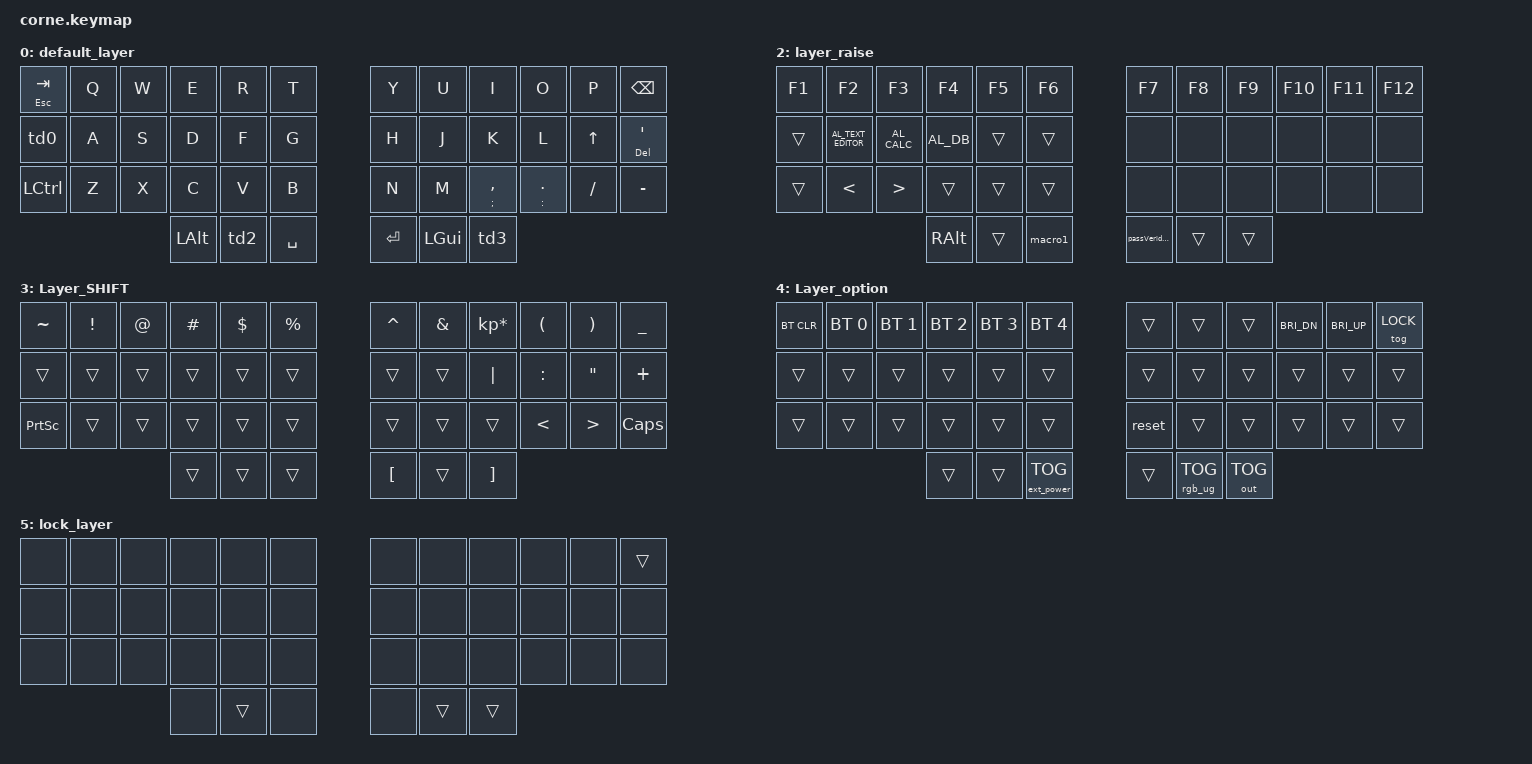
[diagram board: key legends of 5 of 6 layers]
//https://zmk.dev/docs/codes
//https://zmk.dev/docs/development/new-shield

#include <behaviors.dtsi>
#include <dt-bindings/zmk/keys.h>
#include <dt-bindings/zmk/bt.h>
#include <dt-bindings/zmk/rgb.h>
#include <dt-bindings/zmk/backlight.h>
#include <dt-bindings/zmk/ext_power.h>
#include <dt-bindings/zmk/outputs.h>
#include <dt-bindings/zmk/mouse.h>

#define LOWER 1
#define RAISE 2
#define SHIFT 3
#define OPTION 4
#define LOCK 5

/*
&mt es una abreviatura de "mod-tap". Este comportamiento permite que una tecla funcione como un modificador 
(como Shift, Ctrl, Alt, etc.) cuando se mantiene presionada, y como una tecla normal cuando se pulsa y se suelta 
rápidamente. Por ejemplo, &mt LSFT A hará que una tecla funcione como "A" cuando se pulsa y se suelta rápidamente, 
y como Shift izquierdo cuando se mantiene presionada.

&kt es una abreviatura de "key tap". Este comportamiento permite que una tecla funcione como una tecla normal cuando 
se pulsa y se suelta rápidamente, pero también puede tener un comportamiento diferente si se mantiene presionada. Sin 
embargo, a diferencia de &mt, &kt no está limitado a los modificadores y puede asignar cualquier comportamiento a la 
acción de mantener presionada.

Por lo tanto, la principal diferencia entre &mt y &kt es que &mt está limitado a los modificadores para la acción de 
mantener presionada, mientras que &kt puede asignar cualquier comportamiento a la acción de mantener presionada.
*/

&mmv {    
        time-to-max-speed-ms = <1000>;
        acceleration-exponent=<1>;
};
&mwh {    
        time-to-max-speed-ms = <2000>;
        acceleration-exponent=<0>;
}; 
/ {
    behaviors {
        ht: hold-tap {
            compatible = "zmk,behavior-hold-tap";
            label = "hold-tap";
            #binding-cells = <2>;
            tapping_term_ms = <200>;
            //flavor = "tap-preferred"; por defecto en situaciones ambiguas que haga el hold
            bindings =
                <&kp>,
                <&kp>;
        };
        td0: tap_dance_CAPSLOCK {
            compatible = "zmk,behavior-tap-dance";
            #binding-cells = <0>;
            tapping-term-ms = <200>;
            bindings = <&kp LSHFT>, <&kp CAPSLOCK>;
        };

        td1: tap_dance { //generico
            compatible = "zmk,behavior-tap-dance";
            #binding-cells = <2>;
            tapping-term-ms = <200>;
            bindings = <&kp >, <&kp >;
        };

        td2:tap_dance_toggle_capa{
            compatible = "zmk,behavior-tap-dance";
            #binding-cells = <0>;
            tapping-term-ms = <200>;
            bindings = <&tog LOWER>, <&tog OPTION>;
        }

        td3:tap_dance_mo_toggle{
            compatible = "zmk,behavior-tap-dance";
            #binding-cells = <0>;
            tapping-term-ms = <200>;
            bindings = <&mo RAISE>, <&tog LOCK>;
        }
    };
    
    conditional_layers {
        compatible = "zmk,conditional-layers";

        tri_layer {
            if-layers = <LOWER RAISE>;
            then-layer = <OPTION>;
        };
    };
	
    macros {
        macro1: macro1 {
            compatible = "zmk,behavior-macro";
            label = "alt_f4";
            #binding-cells = <0>;
            bindings = <&kp LALT &kp F4>;
        };
        passVeridata: passVeridata {
            compatible = "zmk,behavior-macro";
            label = "pass-veridata";
            #binding-cells = <0>;
            bindings = <&kp A &kp B &kp C &kp D &kp UNDER &kp KP_N1 &kp KP_N2 &kp KP_N3 &kp KP_N4>;
        };
    };
    
    keymap {
        compatible = "zmk,keymap";

        default_layer {
            bindings = <
                &ht ESC TAB     &kp Q       &kp W       &kp E       &kp R   &kp T               &kp Y       &kp U       &kp I           &kp O           &kp P       &kp BACKSPACE
                &td0        &kp A       &kp S       &kp D       &kp F   &kp G               &kp H       &kp J       &kp K           &kp L           &kp UP      &ht DELETE SQT
                &kp LCTRL   &kp Z       &kp X       &kp C       &kp V   &kp B               &kp N       &kp M       &ht SEMI COMMA  &ht COLON DOT   &kp SLASH   &kp MINUS
                                                    &kp LALT    &td2    &kp SPACE           &kp ENTER   &kp LGUI    &td3
            >;
        };
		// number arrows and media
        layer_lower {
            bindings = <
                &ht ESC TAB &kp KP_N1       &kp KP_N2       &kp KP_N3           &kp KP_N4   &kp KP_N5                   &kp KP_N6   &kp KP_N7   &kp KP_N8    &kp KP_N9      &kp KP_N0   &kp BACKSPACE
                &trans      &kp C_VOL_UP    &kp K_VOL_DN    &kp C_MUTE          &none       &none                       &none       &kp UP      &none        &none          &none       &kp DELETE
                &trans      &ht C_RW C_PREV &ht C_FF C_NEXT &kp C_PLAY_PAUSE    &kp HOME    &kp END                     &kp LEFT    &kp DOWN    &kp RIGHT    &ht COLON DOT  &trans      &kp PRINTSCREEN
                                                            aaaaaaaaaaaaaaaaaaaaaaa&trans              &trans      &trans                      &trans      &kp RALT    &trans 
            >;
        };

        layer_raise {
            bindings = <
                &kp F1  &kp F2                  &kp F3          &kp F4      &kp F5  &kp F6                  &kp F7          &kp F8  &kp F9  &kp F10            &kp F11   &kp F12
                &trans  &kp C_AL_TEXT_EDITOR    &kp C_AL_CALC   &kp C_AL_DB &trans  &trans                  &none           &none   &none   &none           &none            &none
                &trans  &kp LT                  &kp GT          &trans      &trans  &trans                  &none           &none   &none   &none &none  &none
                                                                &kp RALT    &trans  &macro1                 &passVeridata   &trans  &trans
            >;
        };

        Layer_SHIFT {
            bindings = <
                &kp TILDE        &kp EXCL        &kp AT         &kp HASH       &kp DLLR        &kp PRCNT       &kp CARET       &kp AMPS       &kp KP_MULTIPLY       &kp LPAR       &kp RPAR       &kp UNDERSCORE
                &trans           &trans          &trans         &trans         &trans          &trans          &trans          &trans         &kp PIPE               &kp COLON      &kp DOUBLE_QUOTES  &kp PLUS
                &kp PRINTSCREEN  &trans          &trans         &trans         &trans          &trans          &trans          &trans         &trans                &kp LESS_THAN  &kp GREATER_THAN   &kp CAPSLOCK
                                            &trans           &trans          &trans         &kp LBKT        &trans             &kp RBKT
            >;
        };


        Layer_option {
            bindings = <
                &bt BT_CLR  &bt BT_SEL 0    &bt BT_SEL 1    &bt BT_SEL 2    &bt BT_SEL 3    &bt BT_SEL 4                &trans  &trans          &trans      &kp C_BRI_DN        &kp C_BRI_UP     &tog LOCK
                &trans      &trans          &trans          &trans          &trans          &trans                      &trans  &trans          &trans      &trans   &trans &trans
                &trans      &trans          &trans          &trans          &trans          &trans                      &reset  &trans          &trans      &trans   &trans &trans
                                                            &trans          &trans          &ext_power EP_TOG           &trans  &rgb_ug RGB_TOG &out OUT_TOG 
            >;
        };
        // 3 phim Lower+Raise+Backspace bat/tat che do khoa phim
        lock_layer {
            bindings = <
                &none      &none      &none      &none      &none      &none                            &none      &none      &none      &none      &none      &trans
                &none      &none      &none      &none      &none      &none                            &none      &none      &none      &none      &none      &none
                &none      &none      &none      &none      &none      &none                            &none      &none      &none      &none      &none      &none
                                                 &none      &trans     &none                            &none      &trans     &trans
            >;
        };
    };
};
